# STM32L052 register map
File version: 1.0
CPU: CM0+ r0p0, little endian, MPU, no FPU, 4 interrupt priority bits
Registers are 32-bit, read-write, reset 0x0 unless marked. A register's access mark holds for its fields unless they carry their own. Offsets are from the block's base; [hi:lo] are bit positions; {n}, {i} and the like mark numbered series.

## PWR — Power control
Base 0x40007000
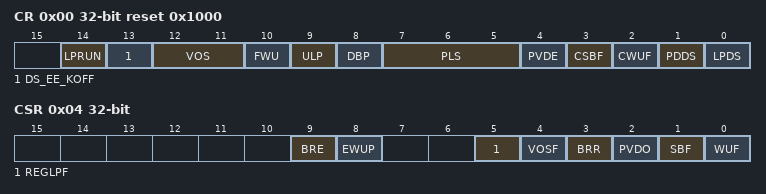
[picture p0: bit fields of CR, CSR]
0x00 CR reset 0x1000 — power control register
  [14] LPRUN — Low power run mode
  [13] DS_EE_KOFF — Deep sleep mode with Flash memory kept off
  [12:11] VOS — Voltage scaling range selection
  [10] FWU — Fast wakeup
  [9] ULP — Ultra-low-power mode
  [8] DBP — Disable backup domain write protection
  [7:5] PLS — PVD level selection
  [4] PVDE — Power voltage detector enable
  [3] CSBF — Clear standby flag
  [2] CWUF — Clear wakeup flag
  [1] PDDS — Power down deepsleep
  [0] LPDS — Low-power deep sleep
0x04 CSR access per field — power control/status register
  [9] BRE rw — Backup regulator enable
  [8] EWUP rw — Enable WKUP pin
  [5] REGLPF ro — Regulator LP flag
  [4] VOSF ro — Voltage Scaling select flag
  [3] BRR ro — Backup regulator ready
  [2] PVDO ro — PVD output
  [1] SBF ro — Standby flag
  [0] WUF ro — Wakeup flag

## RNG — Random number generator
Base 0x40025000
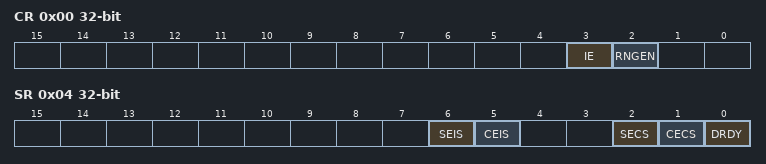
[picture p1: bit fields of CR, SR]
0x00 CR — control register
  [3] IE — Interrupt enable
  [2] RNGEN — Random number generator enable
0x04 SR access per field — status register
  [6] SEIS rw — Seed error interrupt status
  [5] CEIS rw — Clock error interrupt status
  [2] SECS ro — Seed error current status
  [1] CECS ro — Clock error current status
  [0] DRDY ro — Data ready
0x08 DR ro — data register
  [31:0] RNDATA — Random data

## Flash
Base 0x40022000
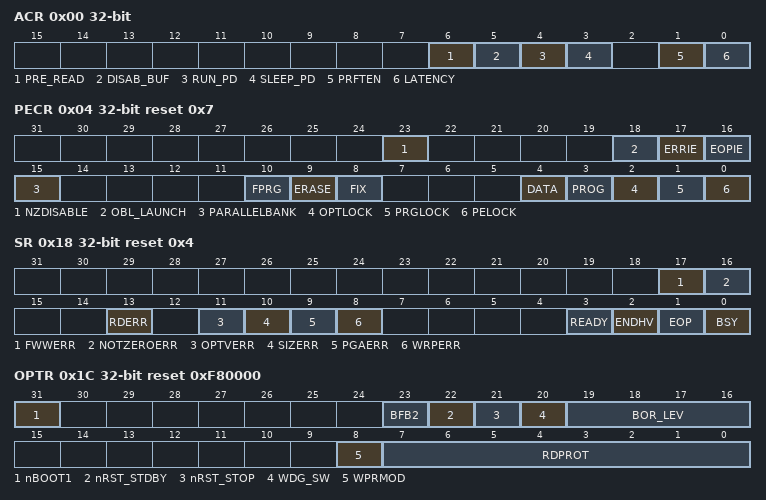
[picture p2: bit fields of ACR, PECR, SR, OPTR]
0x00 ACR — Access control register
  [6] PRE_READ — Pre-read data address
  [5] DISAB_BUF — Disable Buffer
  [4] RUN_PD — Flash mode during Run
  [3] SLEEP_PD — Flash mode during Sleep
  [1] PRFTEN — Prefetch enable
  [0] LATENCY
0x04 PECR reset 0x7 — Program/erase control register
  [23] NZDISABLE — Non-Zero check notification disable
  [18] OBL_LAUNCH — Launch the option byte loading
  [17] ERRIE — Error interrupt enable
  [16] EOPIE — End of programming interrupt enable
  [15] PARALLELBANK — Parallel bank mode
  [10] FPRG — Half Page/Double Word programming mode
  [9] ERASE — Page or Double Word erase mode
  [8] FIX — Fixed time data write for Byte, Half Word and Word programming
  [4] DATA — Data EEPROM selection
  [3] PROG — Program memory selection
  [2] OPTLOCK — Option bytes block lock
  [1] PRGLOCK — Program memory lock
  [0] PELOCK — FLASH_PECR and data EEPROM lock
0x08 PDKEYR wo — Power down key register
  [31:0] PDKEYR — RUN_PD in FLASH_ACR key
0x0C PEKEYR wo — Program/erase key register
  [31:0] PEKEYR — FLASH_PEC and data EEPROM key
0x10 PRGKEYR wo — Program memory key register
  [31:0] PRGKEYR — Program memory key
0x14 OPTKEYR wo — Option byte key register
  [31:0] OPTKEYR — Option byte key
0x18 SR access per field reset 0x4 — Status register
  [17] FWWERR rw
  [16] NOTZEROERR rw
  [13] RDERR rw
  [11] OPTVERR rw — Option validity error
  [10] SIZERR rw — Size error
  [9] PGAERR rw — Programming alignment error
  [8] WRPERR rw — Write protected error
  [3] READY ro — Flash memory module ready after low power mode
  [2] ENDHV ro — End of high voltage
  [1] EOP ro — End of operation
  [0] BSY ro — Write/erase operations in progress
0x1C OPTR ro reset 0xF80000 — Option byte register
  [31] nBOOT1
  [23] BFB2
  [22] nRST_STDBY
  [21] nRST_STOP
  [20] WDG_SW
  [19:16] BOR_LEV
  [8] WPRMOD
  [7:0] RDPROT — Read protection
0x20 WRPROT1 ro — Write protection register
  [31:0] WRPROT1 — Write protection
0x80 WRPROT2 ro — Write protection register
  [15:0] WRPROT2 — Write protection

## EXTI — External interrupt/event controller
Base 0x40010400
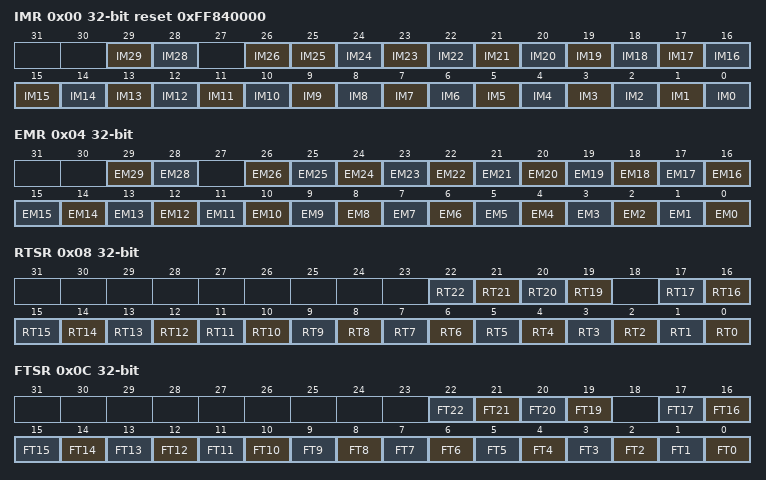
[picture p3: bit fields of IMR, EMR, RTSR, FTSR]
0x00 IMR reset 0xFF840000 — Interrupt mask register (EXTI_IMR)
  [29] IM29 — Interrupt Mask on line 27
  [28] IM28 — Interrupt Mask on line 27
  [26] IM26 — Interrupt Mask on line 27
  [n] IM{n} (n=0..25) — Interrupt Mask on line {n}
0x04 EMR — Event mask register (EXTI_EMR)
  [29] EM29 — Event Mask on line 29
  [28] EM28 — Event Mask on line 28
  [n] EM{n} (n=0..26) — Event Mask on line {n}
0x08 RTSR — Rising Trigger selection register (EXTI_RTSR)
  [n] RT{n} (n=19..22) — Rising trigger event configuration of line {n}
  [n] RT{n} (n=0..17) — Rising trigger event configuration of line {n}
0x0C FTSR — Falling Trigger selection register (EXTI_FTSR)
  [n] FT{n} (n=19..22) — Falling trigger event configuration of line {n}
  [n] FT{n} (n=0..17) — Falling trigger event configuration of line {n}
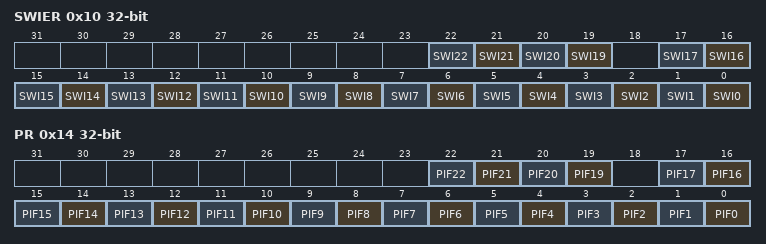
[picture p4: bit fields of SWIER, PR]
0x10 SWIER — Software interrupt event register (EXTI_SWIER)
  [n] SWI{n} (n=19..22) — Software Interrupt on line {n}
  [n] SWI{n} (n=0..17) — Software Interrupt on line {n}
0x14 PR — Pending register (EXTI_PR)
  [n] PIF{n} (n=19..22) — Pending bit {n}
  [n] PIF{n} (n=0..17) — Pending bit {n}
